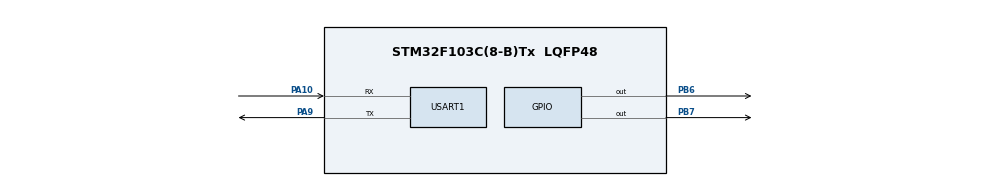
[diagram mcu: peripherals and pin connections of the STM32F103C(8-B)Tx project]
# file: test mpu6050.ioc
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Mcu.Family=STM32F1
Mcu.Name=STM32F103C(8-B)Tx
Mcu.Package=LQFP48
NVIC.PriorityGroup=NVIC_PRIORITYGROUP_4
PA10.Mode=Asynchronous
PA10.Signal=USART1_RX
PA9.Mode=Asynchronous
PA9.Signal=USART1_TX
PB6.GPIO_ModeDefaultOutputPP=GPIO_MODE_OUTPUT_OD
PB6.GPIO_Speed=GPIO_SPEED_FREQ_MEDIUM
PB6.Signal=GPIO_Output
PB7.GPIO_ModeDefaultOutputPP=GPIO_MODE_OUTPUT_OD
PB7.GPIO_Speed=GPIO_SPEED_FREQ_MEDIUM
PB7.Signal=GPIO_Output
PD0-OSC_IN.Mode=HSE-External-Oscillator
PD0-OSC_IN.Signal=RCC_OSC_IN
PD1-OSC_OUT.Mode=HSE-External-Oscillator
PD1-OSC_OUT.Signal=RCC_OSC_OUT
ProjectManager.HeapSize=0x200
ProjectManager.StackSize=0x400
ProjectManager.TargetToolchain=MDK-ARM V5
RCC.APB1Freq_Value=8000000
RCC.APB2Freq_Value=8000000
VP_SYS_VS_ND.Mode=No_Debug
board=test mpu6050

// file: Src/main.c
/**
  ******************************************************************************
  * File Name          : main.c
  * Description        : Main program body
  ******************************************************************************
  *
  * COPYRIGHT(c) 2017 STMicroelectronics
  *
  * Redistribution and use in source and binary forms, with or without modification,
  * are permitted provided that the following conditions are met:
  *   1. Redistributions of source code must retain the above copyright notice,
  *      this list of conditions and the following disclaimer.
  *   2. Redistributions in binary form must reproduce the above copyright notice,
  *      this list of conditions and the following disclaimer in the documentation
  *      and/or other materials provided with the distribution.
  *   3. Neither the name of STMicroelectronics nor the names of its contributors
  *      may be used to endorse or promote products derived from this software
  *      without specific prior written permission.
  *
  * THIS SOFTWARE IS PROVIDED BY THE COPYRIGHT HOLDERS AND CONTRIBUTORS "AS IS"
  * AND ANY EXPRESS OR IMPLIED WARRANTIES, INCLUDING, BUT NOT LIMITED TO, THE
  * IMPLIED WARRANTIES OF MERCHANTABILITY AND FITNESS FOR A PARTICULAR PURPOSE ARE
  * DISCLAIMED. IN NO EVENT SHALL THE COPYRIGHT HOLDER OR CONTRIBUTORS BE LIABLE
  * FOR ANY DIRECT, INDIRECT, INCIDENTAL, SPECIAL, EXEMPLARY, OR CONSEQUENTIAL
  * DAMAGES (INCLUDING, BUT NOT LIMITED TO, PROCUREMENT OF SUBSTITUTE GOODS OR
  * SERVICES; LOSS OF USE, DATA, OR PROFITS; OR BUSINESS INTERRUPTION) HOWEVER
  * CAUSED AND ON ANY THEORY OF LIABILITY, WHETHER IN CONTRACT, STRICT LIABILITY,
  * OR TORT (INCLUDING NEGLIGENCE OR OTHERWISE) ARISING IN ANY WAY OUT OF THE USE
  * OF THIS SOFTWARE, EVEN IF ADVISED OF THE POSSIBILITY OF SUCH DAMAGE.
  *
  ******************************************************************************
  */
#include "main.h"
#include "stm32f1xx_hal.h"
#include "stm32f1xx_it.h"
#include "bsp_debug_usart.h"
#include "bsp_i2c.h"
#include "mpu6050.h"

UART_HandleTypeDef huart1;

/* USER CODE BEGIN PV */
/* Private variables ---------------------------------------------------------*/

/* USER CODE END PV */

void SystemClock_Config(void);
void Error_Handler(void);
static void MX_GPIO_Init(void);
static void MX_USART1_UART_Init(void);

/* USER CODE BEGIN PFP */
/* Private function prototypes -----------------------------------------------*/

/* USER CODE END PFP */

int main(void)
{

  /* USER CODE BEGIN 1 */
short Accel[3];
	short Gyro [3];
	short Temp;
  /* USER CODE END 1 */

  /* MCU Configuration----------------------------------------------------------*/

  /* Reset of all peripherals, Initializes the Flash interface and the Systick. */
  HAL_Init();

  /* Configure the system clock */
  SystemClock_Config();

  /* Initialize all configured peripherals */
  MX_GPIO_Init();
  MX_USART1_UART_Init();

  /* USER CODE BEGIN 2 */
   I2C_InitGPIO();
  MPU6050_Init();

  /* USER CODE END 2 */

  /* Infinite loop */
  while (1)
  {
 MPU6050ReadAcc(Accel);

      printf("\r\n���ٶȣ�%8d%8d%8d",Accel[0],Accel[1],Accel[2]);

      MPU6050ReadGyro(Gyro);
      printf("������: %8d%8d%8d    ",Gyro[0],Gyro[1],Gyro[2]);
      HAL_Delay(10);
  }

}

/** System Clock Configuration
*/
void SystemClock_Config(void)
{

  RCC_OscInitTypeDef RCC_OscInitStruct;
  RCC_ClkInitTypeDef RCC_ClkInitStruct;

    /**Initializes the CPU, AHB and APB busses clocks
    */
  RCC_OscInitStruct.OscillatorType = RCC_OSCILLATORTYPE_HSI;
  RCC_OscInitStruct.HSIState = RCC_HSI_ON;
  RCC_OscInitStruct.HSICalibrationValue = 16;
  RCC_OscInitStruct.PLL.PLLState = RCC_PLL_NONE;
  if (HAL_RCC_OscConfig(&RCC_OscInitStruct) != HAL_OK)
  {
    Error_Handler();
  }

    /**Initializes the CPU, AHB and APB busses clocks
    */
  RCC_ClkInitStruct.ClockType = RCC_CLOCKTYPE_HCLK|RCC_CLOCKTYPE_SYSCLK
                              |RCC_CLOCKTYPE_PCLK1|RCC_CLOCKTYPE_PCLK2;
  RCC_ClkInitStruct.SYSCLKSource = RCC_SYSCLKSOURCE_HSI;
  RCC_ClkInitStruct.AHBCLKDivider = RCC_SYSCLK_DIV1;
  RCC_ClkInitStruct.APB1CLKDivider = RCC_HCLK_DIV1;
  RCC_ClkInitStruct.APB2CLKDivider = RCC_HCLK_DIV1;

  if (HAL_RCC_ClockConfig(&RCC_ClkInitStruct, FLASH_LATENCY_0) != HAL_OK)
  {
    Error_Handler();
  }

    /**Configure the Systick interrupt time
    */
  HAL_SYSTICK_Config(HAL_RCC_GetHCLKFreq()/1000);

    /**Configure the Systick
    */
  HAL_SYSTICK_CLKSourceConfig(SYSTICK_CLKSOURCE_HCLK);

  /* SysTick_IRQn interrupt configuration */
  HAL_NVIC_SetPriority(SysTick_IRQn, 0, 0);
}

/* USART1 init function */
static void MX_USART1_UART_Init(void)
{

  huart1.Instance = USART1;
  huart1.Init.BaudRate = 115200;
  huart1.Init.WordLength = UART_WORDLENGTH_8B;
  huart1.Init.StopBits = UART_STOPBITS_1;
  huart1.Init.Parity = UART_PARITY_NONE;
  huart1.Init.Mode = UART_MODE_TX_RX;
  huart1.Init.HwFlowCtl = UART_HWCONTROL_NONE;
  huart1.Init.OverSampling = UART_OVERSAMPLING_16;
  if (HAL_UART_Init(&huart1) != HAL_OK)
  {
    Error_Handler();
  }

}

/** Configure pins as
        * Analog
        * Input
        * Output
        * EVENT_OUT
        * EXTI
*/
static void MX_GPIO_Init(void)
{

  GPIO_InitTypeDef GPIO_InitStruct;

  /* GPIO Ports Clock Enable */
  __HAL_RCC_GPIOD_CLK_ENABLE();
  __HAL_RCC_GPIOA_CLK_ENABLE();
  __HAL_RCC_GPIOB_CLK_ENABLE();

  /*Configure GPIO pin Output Level */
  HAL_GPIO_WritePin(GPIOB, GPIO_PIN_6|GPIO_PIN_7, GPIO_PIN_RESET);

  /*Configure GPIO pins : PB6 PB7 */
  GPIO_InitStruct.Pin = GPIO_PIN_6|GPIO_PIN_7;
  GPIO_InitStruct.Mode = GPIO_MODE_OUTPUT_OD;
  GPIO_InitStruct.Speed = GPIO_SPEED_FREQ_MEDIUM;
  HAL_GPIO_Init(GPIOB, &GPIO_InitStruct);

}

void Error_Handler(void)
{
  while(1)
  {
  }
}

/************************ (C) COPYRIGHT STMicroelectronics *****END OF FILE****/
